AUTOSAR XML (schema 4-2-2)
package /ComponentTypes
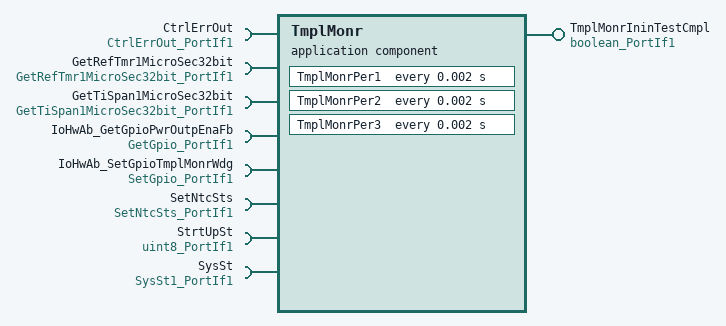
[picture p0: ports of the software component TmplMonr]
  application sw component type TmplMonr
    provide port TmplMonrIninTestCmpl: nonqueued-sender-com-spec{data-element=Logl, init-value=0}, provided-interface=boolean_PortIf1
    8 x require port:
      CtrlErrOut: client-com-spec=Oper, required-interface=CtrlErrOut_PortIf1
      GetRefTmr1MicroSec32bit: client-com-spec=Oper, required-interface=GetRefTmr1MicroSec32bit_PortIf1
      GetTiSpan1MicroSec32bit: client-com-spec=Oper, required-interface=GetTiSpan1MicroSec32bit_PortIf1
      IoHwAb_GetGpioPwrOutpEnaFb: client-com-spec=Oper, required-interface=GetGpio_PortIf1
      IoHwAb_SetGpioTmplMonrWdg: client-com-spec=Oper, required-interface=SetGpio_PortIf1
      SetNtcSts: client-com-spec=Oper, required-interface=SetNtcSts_PortIf1
      StrtUpSt: nonqueued-receiver-com-spec{data-element=Val, filter=data-filter-type=ALWAYS, init-value=0}, required-interface=uint8_PortIf1
      SysSt: nonqueued-receiver-com-spec{data-element=Val, filter=data-filter-type=ALWAYS, init-value=3}, required-interface=SysSt1_PortIf1
    behavior TmplMonr_InternalBehavior
      ar-typed-per-instance-memorys:
        9 x data, all with sw-calibration-access=READ-ONLY:
          AvrgElpdTiMicroSec: type=uint32
          TmplMonrIninCntr: type=uint8
          TmplMonrIninTestCmplFlg: type=boolean
          TmplMonrNtc40PrmByte: type=uint8
          TmplMonrSpiReadWrOrderFlg1: type=boolean
          TmplMonrSpiReadWrOrderFlg2: type=boolean
          TmplMonrWdgRstrtCnt: type=uint8
          TrsmErrCntr: type=uint16
          TrsmErrNtcThd: type=uint8
      init event TmplMonr_InitEvent: start-on-event=TmplMonrInit1
      timing event TMT_TmplMonrPer1: start-on-event=TmplMonrPer1, period=0.002
      timing event TMT_TmplMonrPer2: start-on-event=TmplMonrPer2, period=0.002
      timing event TMT_TmplMonrPer2_1: start-on-event=TmplMonrPer3, period=0.002
      explicit-inter-runnable-variables:
        data ElpdTiMicroSec: type=uint32, init-value=0
      4 x runnable:
        TmplMonrInit1
          data-send-points:
            access SEND_TmplMonrIninTestCmpl_Logl: accessed-variable=TmplMonrIninTestCmpl.Logl
        TmplMonrPer1
          data-receive-point-by-arguments:
            access REC_StrtUpSt_Val: accessed-variable=StrtUpSt.Val
          data-send-points:
            access SEND_TmplMonrIninTestCmpl_Logl: accessed-variable=TmplMonrIninTestCmpl.Logl
          5 x sync call, all with timeout=0:
            SC_CtrlErrOut_Oper: operation=CtrlErrOut.Oper
            SC_GetRefTmr1MicroSec32bit_Oper: operation=GetRefTmr1MicroSec32bit.Oper
            SC_IoHwAb_GetGpioPwrOutpEnaFb_Oper: operation=IoHwAb_GetGpioPwrOutpEnaFb.Oper
            SC_IoHwAb_SetGpioTmplMonrWdg_Oper_1: operation=IoHwAb_SetGpioTmplMonrWdg.Oper
            SC_SetNtcSts_Oper_1: operation=SetNtcSts.Oper
          written-local-variables:
            access WRITE_ElpdTiMicroSec: accessed-variable=ElpdTiMicroSec
        TmplMonrPer2
          read-local-variables:
            access READ_ElpdTiMicroSec: accessed-variable=ElpdTiMicroSec
          sync call SC_GetTiSpan1MicroSec32bit_Oper: operation=GetTiSpan1MicroSec32bit.Oper, timeout=0
          sync call SC_IoHwAb_SetGpioTmplMonrWdg_Oper_1: operation=IoHwAb_SetGpioTmplMonrWdg.Oper, timeout=0
        TmplMonrPer3
          data-receive-point-by-arguments:
            access REC_SysSt_Val: accessed-variable=SysSt.Val
          sync call SC_GetRefTmr1MicroSec32bit_Oper: operation=GetRefTmr1MicroSec32bit.Oper, timeout=0
          sync call SC_GetTiSpan1MicroSec32bit_Oper: operation=GetTiSpan1MicroSec32bit.Oper, timeout=0
  swc implementation TmplMonr_Implementation: behavior=TmplMonr_InternalBehavior
    code-descriptors:
      code Default: artifact-descriptors=autosar-engineering-object={short-label=Default, category=SWSRC}
